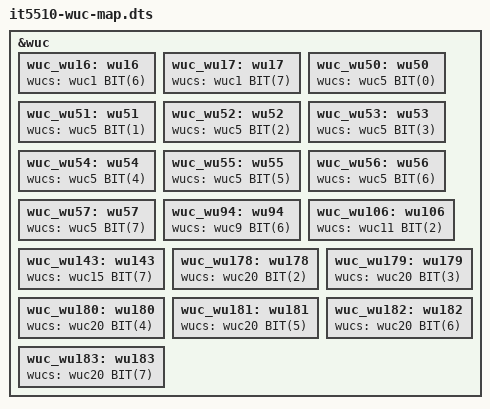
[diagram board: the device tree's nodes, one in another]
/*
 * Copyright (c) 2026 ITE Corporation. All Rights Reserved.
 *
 * SPDX-License-Identifier: Apache-2.0
 */

#include <ite/it51xxx-wuc-map.dtsi>

&wuc {
	/* WUC group 1 */
	/omit-if-no-ref/ wuc_wu16: wu16 {
		wucs = <&wuc1 BIT(6)>; /* GPN0 */
	};

	/omit-if-no-ref/ wuc_wu17: wu17 {
		wucs = <&wuc1 BIT(7)>; /* GPN1 */
	};

	/* WUC group 5 */
	/omit-if-no-ref/ wuc_wu50: wu50 {
		wucs = <&wuc5 BIT(0)>; /* GPK0 */
	};

	/omit-if-no-ref/ wuc_wu51: wu51 {
		wucs = <&wuc5 BIT(1)>; /* GPK1 */
	};

	/omit-if-no-ref/ wuc_wu52: wu52 {
		wucs = <&wuc5 BIT(2)>; /* GPK2 */
	};

	/omit-if-no-ref/ wuc_wu53: wu53 {
		wucs = <&wuc5 BIT(3)>; /* GPK3 */
	};

	/omit-if-no-ref/ wuc_wu54: wu54 {
		wucs = <&wuc5 BIT(4)>; /* GPK4 */
	};

	/omit-if-no-ref/ wuc_wu55: wu55 {
		wucs = <&wuc5 BIT(5)>; /* GPK5 */
	};

	/omit-if-no-ref/ wuc_wu56: wu56 {
		wucs = <&wuc5 BIT(6)>; /* GPK6 */
	};

	/omit-if-no-ref/ wuc_wu57: wu57 {
		wucs = <&wuc5 BIT(7)>; /* GPK7 */
	};

	/* WUC group 9 */
	/omit-if-no-ref/ wuc_wu94: wu94 {
		wucs = <&wuc9 BIT(6)>; /* GPB4 */
	};

	/* WUC group 11 */
	/omit-if-no-ref/ wuc_wu106: wu106 {
		wucs = <&wuc11 BIT(2)>; /* GPB7 */
	};

	/* WUC group 15 */
	/omit-if-no-ref/ wuc_wu143: wu143 {
		wucs = <&wuc15 BIT(7)>; /* GPL7 */
	};

	/* WUC group 20 */
	/omit-if-no-ref/ wuc_wu178: wu178 {
		wucs = <&wuc20 BIT(2)>; /* GPN2 */
	};

	/omit-if-no-ref/ wuc_wu179: wu179 {
		wucs = <&wuc20 BIT(3)>; /* GPN3 */
	};

	/omit-if-no-ref/ wuc_wu180: wu180 {
		wucs = <&wuc20 BIT(4)>; /* GPN4 */
	};

	/omit-if-no-ref/ wuc_wu181: wu181 {
		wucs = <&wuc20 BIT(5)>; /* GPN5 */
	};

	/omit-if-no-ref/ wuc_wu182: wu182 {
		wucs = <&wuc20 BIT(6)>; /* GPN6 */
	};

	/omit-if-no-ref/ wuc_wu183: wu183 {
		wucs = <&wuc20 BIT(7)>; /* GPN7 */
	};
};
